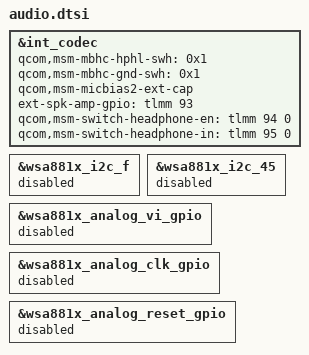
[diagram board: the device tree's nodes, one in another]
&int_codec {
	qcom,msm-mbhc-hphl-swh = <0x1>;
	qcom,msm-mbhc-gnd-swh = <0x1>;
	qcom,msm-micbias2-ext-cap;
	ext-spk-amp-gpio = <&tlmm 93 0>;
	qcom,msm-switch-headphone-en = <&tlmm 94 0>;
	qcom,msm-switch-headphone-in = <&tlmm 95 0>;
	/delete-property/ asoc-wsa-codec-names;
	/delete-property/ asoc-wsa-codec-prefixes;
	/delete-property/ msm-vdd-wsa-switch-supply;
	/delete-property/ qcom,msm-vdd-wsa-switch-voltage;
	/delete-property/ qcom,msm-vdd-wsa-switch-current;
};

&wsa881x_i2c_f {
        status = "disabled";
};

&wsa881x_i2c_45 {
        status = "disabled";
};

&wsa881x_analog_vi_gpio {
        status = "disabled";
};

&wsa881x_analog_clk_gpio {
        status = "disabled";
};

&wsa881x_analog_reset_gpio {
        status = "disabled";
};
